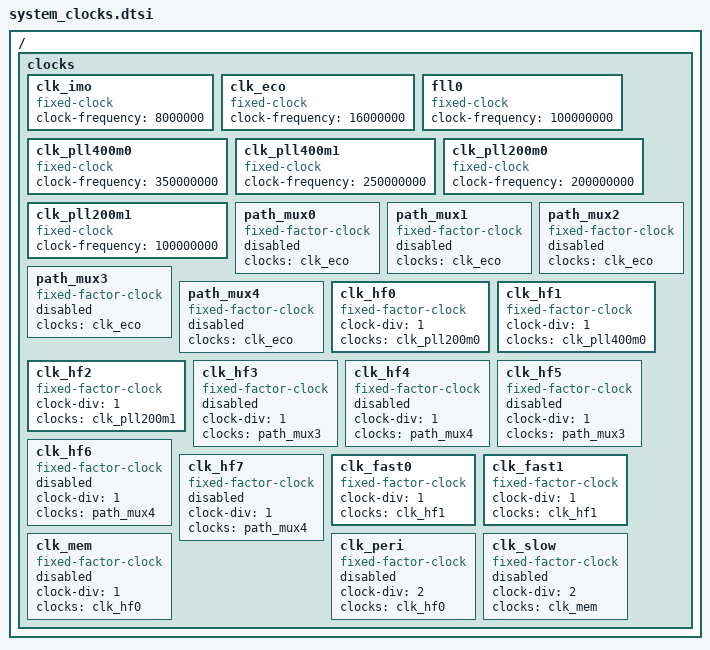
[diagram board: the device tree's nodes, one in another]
/*
 * Copyright (c) 2024 Cypress Semiconductor Corporation (an Infineon company) or
 * an affiliate of Cypress Semiconductor Corporation
 *
 * SPDX-License-Identifier: Apache-2.0
 */

#include "clock_source_def.h"

/ {
	clocks {
		/* imo */
		clk_imo: clk_imo {
			compatible = "fixed-clock";
			#clock-cells = <0>;
			clock-frequency = <8000000>;
			status = "okay";
		};

		/* eco */
		clk_eco: clk_eco {
			compatible = "fixed-clock";
			#clock-cells = <0>;
			clock-frequency = <16000000>;
			status = "okay";
		};

		/* fll */
		fll0: fll0 {
			compatible = "fixed-clock";
			#clock-cells = <0>;
			clock-frequency = <100000000>;
			status = "okay";
		};

		/* pll400m0 */
		clk_pll400m0: clk_pll400m0 {
			compatible = "fixed-clock";
			#clock-cells = <0>;
			clock-frequency = <350000000>;
			status = "okay";
		};

		/* pll400m1 */
		clk_pll400m1: clk_pll400m1 {
			compatible = "fixed-clock";
			#clock-cells = <0>;
			clock-frequency = <250000000>;
			status = "okay";
		};

		/* pll200m0 */
		clk_pll200m0: clk_pll200m0 {
			compatible = "fixed-clock";
			#clock-cells = <0>;
			clock-frequency = <200000000>;
			status = "okay";
		};

		/* pll200m1 */
		clk_pll200m1: clk_pll200m1 {
			compatible = "fixed-clock";
			#clock-cells = <0>;
			clock-frequency = <100000000>;
			status = "okay";
		};

		/* path mux0 */
		path_mux0: path_mux0 {
			compatible = "fixed-factor-clock";
			#clock-cells = <0>;
			clocks = <&clk_eco>;
			status = "disabled";
		};

		/* path mux1 */
		path_mux1: path_mux1 {
			compatible = "fixed-factor-clock";
			#clock-cells = <0>;
			clocks = <&clk_eco>;
			status = "disabled";
		};

		/* path mux2 */
		path_mux2: path_mux2 {
			compatible = "fixed-factor-clock";
			#clock-cells = <0>;
			clocks = <&clk_eco>;
			status = "disabled";
		};

		/* path mux3 */
		path_mux3: path_mux3 {
			compatible = "fixed-factor-clock";
			#clock-cells = <0>;
			clocks = <&clk_eco>;
			status = "disabled";
		};

		/* path mux4 */
		path_mux4: path_mux4 {
			compatible = "fixed-factor-clock";
			#clock-cells = <0>;
			clocks = <&clk_eco>;
			status = "disabled";
		};

		/* clk_hf0 */
		clk_hf0: clk_hf0 {
			compatible = "fixed-factor-clock";
			#clock-cells = <0>;
			clock-div = <1>;
			clocks = <&clk_pll200m0>;
			status = "okay";
		};

		/* clk_hf1 */
		clk_hf1: clk_hf1 {
			compatible = "fixed-factor-clock";
			#clock-cells = <0>;
			clock-div = <1>;
			clocks = <&clk_pll400m0>;
			status = "okay";
		};

		/* clk_hf2 */
		clk_hf2: clk_hf2 {
			compatible = "fixed-factor-clock";
			#clock-cells = <0>;
			clock-div = <1>;
			clocks = <&clk_pll200m1>;
			status = "okay";
		};

		/* clk_hf3 */
		clk_hf3: clk_hf3 {
			compatible = "fixed-factor-clock";
			#clock-cells = <0>;
			clock-div = <1>;
			clocks = <&path_mux3>;
			status = "disabled";
		};

		/* clk_hf4 */
		clk_hf4: clk_hf4 {
			compatible = "fixed-factor-clock";
			#clock-cells = <0>;
			clock-div = <1>;
			clocks = <&path_mux4>;
			status = "disabled";
		};

		/* clk_hf5 */
		clk_hf5: clk_hf5 {
			compatible = "fixed-factor-clock";
			#clock-cells = <0>;
			clock-div = <1>;
			clocks = <&path_mux3>;
			status = "disabled";
		};

		/* clk_hf6 */
		clk_hf6: clk_hf6 {
			compatible = "fixed-factor-clock";
			#clock-cells = <0>;
			clock-div = <1>;
			clocks = <&path_mux4>;
			status = "disabled";
		};

		/* clk_hf7 */
		clk_hf7: clk_hf7 {
			compatible = "fixed-factor-clock";
			#clock-cells = <0>;
			clock-div = <1>;
			clocks = <&path_mux4>;
			status = "disabled";
		};

		/* clk_fast0 */
		clk_fast0: clk_fast0 {
			compatible = "fixed-factor-clock";
			#clock-cells = <0>;
			clock-div = <1>;
			clocks = <&clk_hf1>;
			status = "okay";
		};

		/* clk_fast1 */
		clk_fast1: clk_fast1 {
			compatible = "fixed-factor-clock";
			#clock-cells = <0>;
			clock-div = <1>;
			clocks = <&clk_hf1>;
			status = "okay";
		};

		/* clk_mem */
		clk_mem: clk_mem {
			compatible = "fixed-factor-clock";
			#clock-cells = <0>;
			clock-div = <1>;
			clocks = <&clk_hf0>;
			status = "disabled";
		};

		/* clk_peri */
		clk_peri: clk_peri {
			compatible = "fixed-factor-clock";
			#clock-cells = <0>;
			clock-div = <2>;
			clocks = <&clk_hf0>;
			status = "disabled";
		};

		/* clk_slow */
		clk_slow: clk_slow {
			compatible = "fixed-factor-clock";
			#clock-cells = <0>;
			clock-div = <2>;
			clocks = <&clk_mem>;
			status = "disabled";
		};
	};
};
